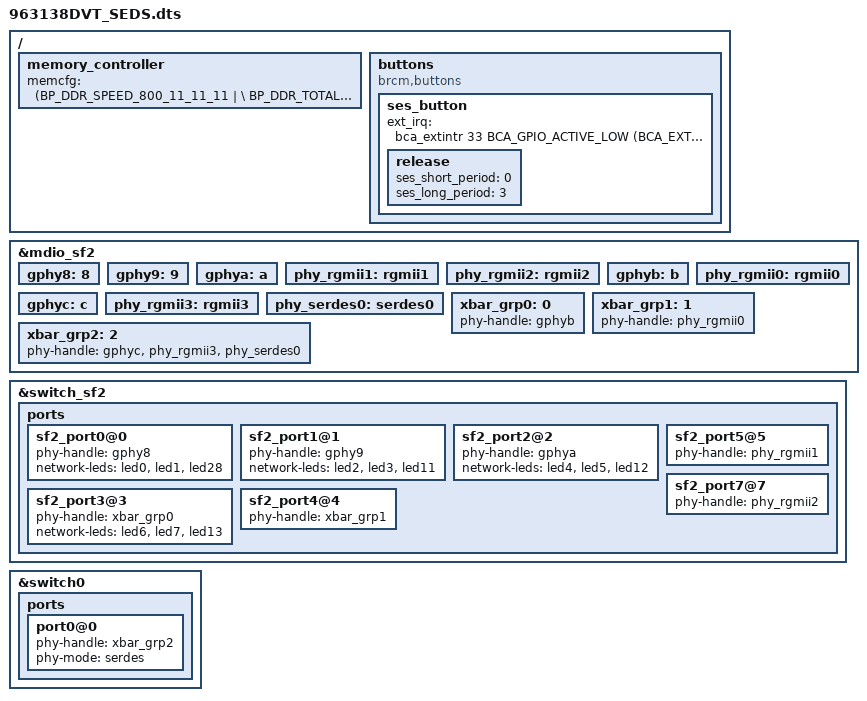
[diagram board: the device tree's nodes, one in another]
#include "63138.dtsi"
#include "963138DVT_leds.dtsi"

/ {
	memory_controller {
		memcfg = <(BP_DDR_SPEED_800_11_11_11   | \
				BP_DDR_TOTAL_SIZE_128MB  | \
				BP_DDR_DEVICE_WIDTH_16)>;
	};

	buttons {
		compatible = "brcm,buttons";

		ses_button {
			ext_irq = <&bca_extintr 33 BCA_GPIO_ACTIVE_LOW (BCA_EXTINTR_TYPE_LOW_LEVEL | BCA_EXTINTR_TYPE_SENSE_LEVEL)>;
			release {
				ses_short_period = <0>;
				ses_long_period = <3>;
			};
		};
	};
};


&mdio_sf2 {
	/* PHYs directly connected to SF2 */
	gphy8:8 {
		status = "okay";
	};
	gphy9:9 {
		status = "okay";
	};
	gphya:a {
		status = "okay";
	};
	phy_rgmii1:rgmii1 {
		status = "okay";
	};
	phy_rgmii2:rgmii2 {
		status = "okay";
	};

	/* PHYs connected to crossbar */
	gphyb:b {
		status = "okay";
	};
	phy_rgmii0:rgmii0 {
		status = "okay";
	};
	gphyc:c {
		status = "okay";
	};
	phy_rgmii3:rgmii3 {
		status = "okay";
	};
	phy_serdes0:serdes0 {
		status = "okay";
	};

	/* Crossbar groups */
	xbar_grp0:0 {
		phy-handle = <&gphyb>;
		status = "okay";
	};
	xbar_grp1:1 {
		phy-handle = <&phy_rgmii0>;
		status = "okay";
	};
	xbar_grp2:2 {
		phy-handle = <&gphyc &phy_rgmii3 &phy_serdes0>;
		status = "okay";
	};
};

&switch_sf2 {
	ports {
		/* ports connect directly */
		sf2_port0@0 {
			phy-handle = <&gphy8>;
			network-leds = <&led0 &led1 &led28>;		
			status = "okay";
		};

		sf2_port1@1 {
			phy-handle = <&gphy9>;
			network-leds = <&led2 &led3 &led11>;
			status = "okay";
		};

		sf2_port2@2 {
			phy-handle = <&gphya>;
			network-leds = <&led4 &led5 &led12>;
			status = "okay";
		};

		sf2_port5@5 {
			phy-handle = <&phy_rgmii1>;
			status = "okay";
		};

		sf2_port7@7 {
			phy-handle = <&phy_rgmii2>;
			status = "okay";
		};
		/* ports connected to crossbar */
		sf2_port3@3 {
			phy-handle = <&xbar_grp0>;
			network-leds = <&led6 &led7 &led13>;
			status = "okay";
		};
		sf2_port4@4 {
			phy-handle = <&xbar_grp1>;
			status = "okay";
		};
	};
};

&switch0 {
	ports {
		
		port0@0 {
			phy-handle = <&xbar_grp2>;
			phy-mode = "serdes";
			status = "okay";
		};
	};
};
